AUTOSAR XML (schema 00049)
package /ComponentTypes
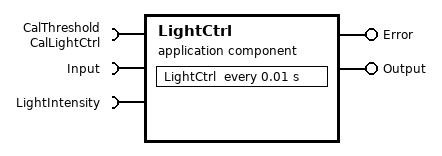
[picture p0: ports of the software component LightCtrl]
  application sw component type LightCtrl
    provide port Error: nonqueued-sender-com-spec{data-element=ErrorCode, init-value=0}, provided-interface=Error
    provide port Output: provided-com-specs=[{data-element=HeadLight, init-value=0}, {data-element=Temperature, init-value=72}], provided-interface=Output
    require port CalThreshold: required-interface=CalLightCtrl
      required-com-specs:
        init-value=70, parameter=Threshold_LightIntensityToOff
        init-value=60, parameter=Threshold_LightIntensityToOn
    require port Input: nonqueued-receiver-com-spec{data-element=LightSwitch, filter=data-filter-type=ALWAYS, init-value=0}, required-interface=Input
    require port LightIntensity: client-com-spec=LightIntensity, required-interface=LightIntensity
    behavior LightCtrl_InternalBehavior: data-type-mapping=TheTypeMappingSet
      timing event TMT_LightCtrl: start-on-event=LightCtrl, period=0.01
      implicit-inter-runnable-variables:
        data InterRunnableVariable: sw-calibration-access=READ-WRITE, type=float32, init-value=22
      runnable LightCtrl
        data-receive-point-by-arguments:
          access REC_Input_AlexSpecialPort_LightSwitch: accessed-variable=Input.LightSwitch
        data-send-points:
          access SEND_Error_ErrorCode: accessed-variable=Error.ErrorCode
          access SEND_Output_HeadLight: accessed-variable=Output.HeadLight
          access SEND_Output_Temperature: accessed-variable=Output.Temperature
        read-local-variables:
          access Read_InterRunnableVariable: accessed-variable=InterRunnableVariable
        sync call SC_LightIntensity_LightIntensity: operation=LightIntensity.LightIntensity
        written-local-variables:
          access WRITE_InterRunnableVariable: accessed-variable=InterRunnableVariable
  swc implementation LightCtrl_Implementation: behavior=LightCtrl_InternalBehavior
    code-descriptors:
      code Default: artifact-descriptors=autosar-engineering-object=category=SWSRC
